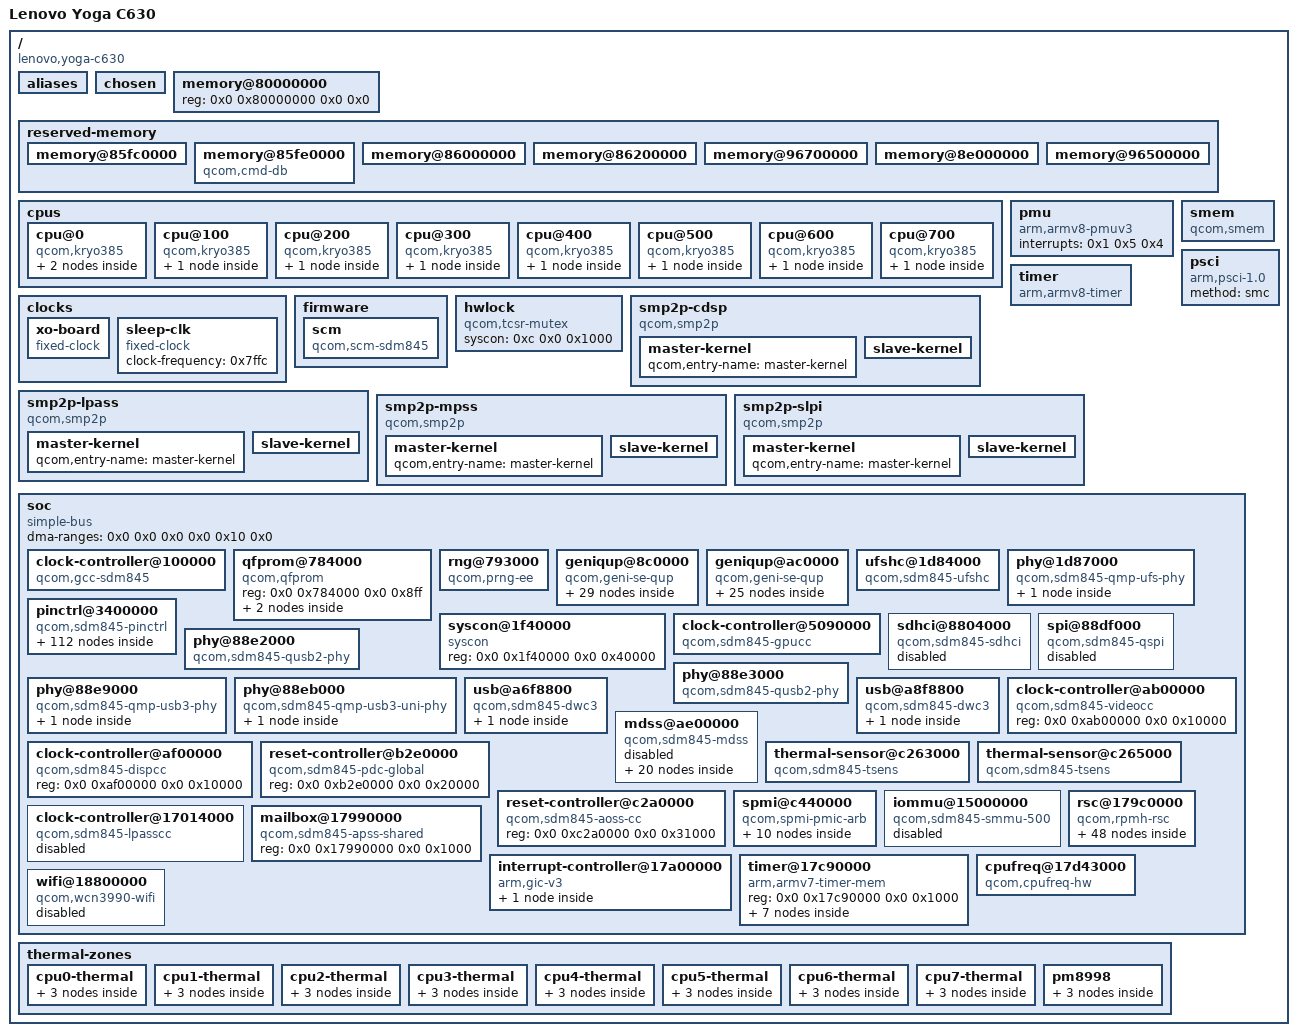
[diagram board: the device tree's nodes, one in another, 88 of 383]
/dts-v1/;

/ {
	interrupt-parent = <0x1>;
	#address-cells = <0x2>;
	#size-cells = <0x2>;
	model = "Lenovo Yoga C630";
	compatible = "lenovo,yoga-c630", "qcom,sdm845";

	aliases {
		i2c0 = "/soc/geniqup@8c0000/i2c@880000";
		i2c1 = "/soc/geniqup@8c0000/i2c@884000";
		i2c2 = "/soc/geniqup@8c0000/i2c@888000";
		i2c3 = "/soc/geniqup@8c0000/i2c@88c000";
		i2c4 = "/soc/geniqup@8c0000/i2c@890000";
		i2c5 = "/soc/geniqup@8c0000/i2c@894000";
		i2c6 = "/soc/geniqup@8c0000/i2c@898000";
		i2c7 = "/soc/geniqup@8c0000/i2c@89c000";
		i2c8 = "/soc/geniqup@ac0000/i2c@a80000";
		i2c9 = "/soc/geniqup@ac0000/i2c@a84000";
		i2c10 = "/soc/geniqup@ac0000/i2c@a88000";
		i2c11 = "/soc/geniqup@ac0000/i2c@a8c000";
		i2c12 = "/soc/geniqup@ac0000/i2c@a90000";
		i2c13 = "/soc/geniqup@ac0000/i2c@a94000";
		i2c14 = "/soc/geniqup@ac0000/i2c@a98000";
		i2c15 = "/soc/geniqup@ac0000/i2c@a9c000";
		spi0 = "/soc/geniqup@8c0000/spi@880000";
		spi1 = "/soc/geniqup@8c0000/spi@884000";
		spi2 = "/soc/geniqup@8c0000/spi@888000";
		spi3 = "/soc/geniqup@8c0000/spi@88c000";
		spi4 = "/soc/geniqup@8c0000/spi@890000";
		spi5 = "/soc/geniqup@8c0000/spi@894000";
		spi6 = "/soc/geniqup@8c0000/spi@898000";
		spi7 = "/soc/geniqup@8c0000/spi@89c000";
		spi8 = "/soc/geniqup@ac0000/spi@a80000";
		spi9 = "/soc/geniqup@ac0000/spi@a84000";
		spi10 = "/soc/geniqup@ac0000/spi@a88000";
		spi11 = "/soc/geniqup@ac0000/spi@a8c000";
		spi12 = "/soc/geniqup@ac0000/spi@a90000";
		spi13 = "/soc/geniqup@ac0000/spi@a94000";
		spi14 = "/soc/geniqup@ac0000/spi@a98000";
		spi15 = "/soc/geniqup@ac0000/spi@a9c000";
		hsuart0 = "/soc/geniqup@8c0000/serial@898000";
	};

	chosen {
	};

	memory@80000000 {
		device_type = "memory";
		reg = <0x0 0x80000000 0x0 0x0>;
	};

	reserved-memory {
		#address-cells = <0x2>;
		#size-cells = <0x2>;
		ranges;

		memory@85fc0000 {
			reg = <0x0 0x85fc0000 0x0 0x20000>;
			no-map;
		};

		memory@85fe0000 {
			compatible = "qcom,cmd-db";
			reg = <0x0 0x85fe0000 0x0 0x20000>;
			no-map;
		};

		memory@86000000 {
			reg = <0x0 0x86000000 0x0 0x200000>;
			no-map;
			phandle = <0xd>;
		};

		memory@86200000 {
			reg = <0x0 0x86200000 0x0 0x2d00000>;
			no-map;
		};

		memory@96700000 {
			reg = <0x0 0x96700000 0x0 0x100000>;
			no-map;
			phandle = <0x62>;
		};

		memory@8e000000 {
			reg = <0x0 0x8e000000 0x0 0x7800000>;
			no-map;
		};

		memory@96500000 {
			reg = <0x0 0x96500000 0x0 0x200000>;
			no-map;
		};
	};

	cpus {
		#address-cells = <0x2>;
		#size-cells = <0x0>;

		cpu@0 {
			device_type = "cpu";
			compatible = "qcom,kryo385";
			reg = <0x0 0x0>;
			enable-method = "psci";
			qcom,freq-domain = <0x2 0x0>;
			next-level-cache = <0x3>;

			l2-cache {
				compatible = "cache";
				next-level-cache = <0x4>;
				phandle = <0x3>;

				l3-cache {
					compatible = "cache";
					phandle = <0x4>;
				};
			};
		};

		cpu@100 {
			device_type = "cpu";
			compatible = "qcom,kryo385";
			reg = <0x0 0x100>;
			enable-method = "psci";
			qcom,freq-domain = <0x2 0x0>;
			next-level-cache = <0x5>;

			l2-cache {
				compatible = "cache";
				next-level-cache = <0x4>;
				phandle = <0x5>;
			};
		};

		cpu@200 {
			device_type = "cpu";
			compatible = "qcom,kryo385";
			reg = <0x0 0x200>;
			enable-method = "psci";
			qcom,freq-domain = <0x2 0x0>;
			next-level-cache = <0x6>;

			l2-cache {
				compatible = "cache";
				next-level-cache = <0x4>;
				phandle = <0x6>;
			};
		};

		cpu@300 {
			device_type = "cpu";
			compatible = "qcom,kryo385";
			reg = <0x0 0x300>;
			enable-method = "psci";
			qcom,freq-domain = <0x2 0x0>;
			next-level-cache = <0x7>;

			l2-cache {
				compatible = "cache";
				next-level-cache = <0x4>;
				phandle = <0x7>;
			};
		};

		cpu@400 {
			device_type = "cpu";
			compatible = "qcom,kryo385";
			reg = <0x0 0x400>;
			enable-method = "psci";
			qcom,freq-domain = <0x2 0x1>;
			next-level-cache = <0x8>;

			l2-cache {
				compatible = "cache";
				next-level-cache = <0x4>;
				phandle = <0x8>;
			};
		};

		cpu@500 {
			device_type = "cpu";
			compatible = "qcom,kryo385";
			reg = <0x0 0x500>;
			enable-method = "psci";
			qcom,freq-domain = <0x2 0x1>;
			next-level-cache = <0x9>;

			l2-cache {
				compatible = "cache";
				next-level-cache = <0x4>;
				phandle = <0x9>;
			};
		};

		cpu@600 {
			device_type = "cpu";
			compatible = "qcom,kryo385";
			reg = <0x0 0x600>;
			enable-method = "psci";
			qcom,freq-domain = <0x2 0x1>;
			next-level-cache = <0xa>;

			l2-cache {
				compatible = "cache";
				next-level-cache = <0x4>;
				phandle = <0xa>;
			};
		};

		cpu@700 {
			device_type = "cpu";
			compatible = "qcom,kryo385";
			reg = <0x0 0x700>;
			enable-method = "psci";
			qcom,freq-domain = <0x2 0x1>;
			next-level-cache = <0xb>;

			l2-cache {
				compatible = "cache";
				next-level-cache = <0x4>;
				phandle = <0xb>;
			};
		};
	};

	pmu {
		compatible = "arm,armv8-pmuv3";
		interrupts = <0x1 0x5 0x4>;
	};

	timer {
		compatible = "arm,armv8-timer";
		interrupts = <0x1 0x1 0x8 0x1 0x2 0x8 0x1 0x3 0x8 0x1 0x0 0x8>;
	};

	clocks {

		xo-board {
			compatible = "fixed-clock";
			#clock-cells = <0x0>;
			clock-frequency = <0x249f000>;
			clock-output-names = "xo_board";
		};

		sleep-clk {
			compatible = "fixed-clock";
			#clock-cells = <0x0>;
			clock-frequency = <0x7ffc>;
		};
	};

	firmware {

		scm {
			compatible = "qcom,scm-sdm845", "qcom,scm";
		};
	};

	hwlock {
		compatible = "qcom,tcsr-mutex";
		syscon = <0xc 0x0 0x1000>;
		#hwlock-cells = <0x1>;
		phandle = <0xe>;
	};

	smem {
		compatible = "qcom,smem";
		memory-region = <0xd>;
		hwlocks = <0xe 0x3>;
	};

	smp2p-cdsp {
		compatible = "qcom,smp2p";
		qcom,smem = <0x5e 0x1b0>;
		interrupts = <0x0 0x240 0x1>;
		mboxes = <0xf 0x6>;
		qcom,local-pid = <0x0>;
		qcom,remote-pid = <0x5>;

		master-kernel {
			qcom,entry-name = "master-kernel";
			#qcom,smem-state-cells = <0x1>;
		};

		slave-kernel {
			qcom,entry-name = "slave-kernel";
			interrupt-controller;
			#interrupt-cells = <0x2>;
		};
	};

	smp2p-lpass {
		compatible = "qcom,smp2p";
		qcom,smem = <0x1bb 0x1ad>;
		interrupts = <0x0 0x9e 0x1>;
		mboxes = <0xf 0xa>;
		qcom,local-pid = <0x0>;
		qcom,remote-pid = <0x2>;

		master-kernel {
			qcom,entry-name = "master-kernel";
			#qcom,smem-state-cells = <0x1>;
		};

		slave-kernel {
			qcom,entry-name = "slave-kernel";
			interrupt-controller;
			#interrupt-cells = <0x2>;
		};
	};

	smp2p-mpss {
		compatible = "qcom,smp2p";
		qcom,smem = <0x1b3 0x1ac>;
		interrupts = <0x0 0x1c3 0x1>;
		mboxes = <0xf 0xe>;
		qcom,local-pid = <0x0>;
		qcom,remote-pid = <0x1>;

		master-kernel {
			qcom,entry-name = "master-kernel";
			#qcom,smem-state-cells = <0x1>;
		};

		slave-kernel {
			qcom,entry-name = "slave-kernel";
			interrupt-controller;
			#interrupt-cells = <0x2>;
		};
	};

	smp2p-slpi {
		compatible = "qcom,smp2p";
		qcom,smem = <0x1e1 0x1ae>;
		interrupts = <0x0 0xac 0x1>;
		mboxes = <0xf 0x1a>;
		qcom,local-pid = <0x0>;
		qcom,remote-pid = <0x3>;

		master-kernel {
			qcom,entry-name = "master-kernel";
			#qcom,smem-state-cells = <0x1>;
		};

		slave-kernel {
			qcom,entry-name = "slave-kernel";
			interrupt-controller;
			#interrupt-cells = <0x2>;
		};
	};

	psci {
		compatible = "arm,psci-1.0";
		method = "smc";
	};

	soc {
		#address-cells = <0x2>;
		#size-cells = <0x2>;
		ranges = <0x0 0x0 0x0 0x0 0x10 0x0>;
		dma-ranges = <0x0 0x0 0x0 0x0 0x10 0x0>;
		compatible = "simple-bus";

		clock-controller@100000 {
			compatible = "qcom,gcc-sdm845";
			reg = <0x0 0x100000 0x0 0x1f0000>;
			#clock-cells = <0x1>;
			#reset-cells = <0x1>;
			#power-domain-cells = <0x1>;
			protected-clocks = <0xbc 0xbb 0xbd>;
			phandle = <0x10>;
		};

		qfprom@784000 {
			compatible = "qcom,qfprom";
			reg = <0x0 0x784000 0x0 0x8ff>;
			#address-cells = <0x1>;
			#size-cells = <0x1>;

			hstx-trim-primary@1eb {
				reg = <0x1eb 0x1>;
				bits = <0x1 0x4>;
				phandle = <0x4f>;
			};

			hstx-trim-secondary@1eb {
				reg = <0x1eb 0x2>;
				bits = <0x6 0x4>;
				phandle = <0x52>;
			};
		};

		rng@793000 {
			compatible = "qcom,prng-ee";
			reg = <0x0 0x793000 0x0 0x1000>;
			clocks = <0x10 0x40>;
			clock-names = "core";
		};

		geniqup@8c0000 {
			compatible = "qcom,geni-se-qup";
			reg = <0x0 0x8c0000 0x0 0x6000>;
			clock-names = "m-ahb", "s-ahb";
			clocks = <0x10 0x64 0x10 0x65>;
			#address-cells = <0x2>;
			#size-cells = <0x2>;
			ranges;
			status = "okay";

			i2c@880000 {
				compatible = "qcom,geni-i2c";
				reg = <0x0 0x880000 0x0 0x4000>;
				clock-names = "se";
				clocks = <0x10 0x44>;
				pinctrl-names = "default";
				pinctrl-0 = <0x11>;
				interrupts = <0x0 0x259 0x4>;
				#address-cells = <0x1>;
				#size-cells = <0x0>;
				status = "disabled";
			};

			spi@880000 {
				compatible = "qcom,geni-spi";
				reg = <0x0 0x880000 0x0 0x4000>;
				clock-names = "se";
				clocks = <0x10 0x44>;
				pinctrl-names = "default";
				pinctrl-0 = <0x12>;
				interrupts = <0x0 0x259 0x4>;
				#address-cells = <0x1>;
				#size-cells = <0x0>;
				status = "disabled";
			};

			serial@880000 {
				compatible = "qcom,geni-uart";
				reg = <0x0 0x880000 0x0 0x4000>;
				clock-names = "se";
				clocks = <0x10 0x44>;
				pinctrl-names = "default";
				pinctrl-0 = <0x13>;
				interrupts = <0x0 0x259 0x4>;
				status = "disabled";
			};

			i2c@884000 {
				compatible = "qcom,geni-i2c";
				reg = <0x0 0x884000 0x0 0x4000>;
				clock-names = "se";
				clocks = <0x10 0x46>;
				pinctrl-names = "default";
				pinctrl-0 = <0x14>;
				interrupts = <0x0 0x25a 0x4>;
				#address-cells = <0x1>;
				#size-cells = <0x0>;
				status = "okay";
				clock-frequency = <0x61a80>;

				hid@2c {
					compatible = "hid-over-i2c";
					reg = <0x2c>;
					hid-descr-addr = <0x20>;
					interrupts-extended = <0x15 0x25 0x1>;
					pinctrl-names = "default";
					pinctrl-0 = <0x16>;
				};

				battery@70 {
					compatible = "some,battery";
					reg = <0x70>;
				};
			};

			spi@884000 {
				compatible = "qcom,geni-spi";
				reg = <0x0 0x884000 0x0 0x4000>;
				clock-names = "se";
				clocks = <0x10 0x46>;
				pinctrl-names = "default";
				pinctrl-0 = <0x17>;
				interrupts = <0x0 0x25a 0x4>;
				#address-cells = <0x1>;
				#size-cells = <0x0>;
				status = "disabled";
			};

			serial@884000 {
				compatible = "qcom,geni-uart";
				reg = <0x0 0x884000 0x0 0x4000>;
				clock-names = "se";
				clocks = <0x10 0x46>;
				pinctrl-names = "default";
				pinctrl-0 = <0x18>;
				interrupts = <0x0 0x25a 0x4>;
				status = "disabled";
			};

			i2c@888000 {
				compatible = "qcom,geni-i2c";
				reg = <0x0 0x888000 0x0 0x4000>;
				clock-names = "se";
				clocks = <0x10 0x48>;
				pinctrl-names = "default";
				pinctrl-0 = <0x19>;
				interrupts = <0x0 0x25b 0x4>;
				#address-cells = <0x1>;
				#size-cells = <0x0>;
				status = "disabled";
			};

			spi@888000 {
				compatible = "qcom,geni-spi";
				reg = <0x0 0x888000 0x0 0x4000>;
				clock-names = "se";
				clocks = <0x10 0x48>;
				pinctrl-names = "default";
				pinctrl-0 = <0x1a>;
				interrupts = <0x0 0x25b 0x4>;
				#address-cells = <0x1>;
				#size-cells = <0x0>;
				status = "disabled";
			};

			serial@888000 {
				compatible = "qcom,geni-uart";
				reg = <0x0 0x888000 0x0 0x4000>;
				clock-names = "se";
				clocks = <0x10 0x48>;
				pinctrl-names = "default";
				pinctrl-0 = <0x1b>;
				interrupts = <0x0 0x25b 0x4>;
				status = "disabled";
			};

			i2c@88c000 {
				compatible = "qcom,geni-i2c";
				reg = <0x0 0x88c000 0x0 0x4000>;
				clock-names = "se";
				clocks = <0x10 0x4a>;
				pinctrl-names = "default";
				pinctrl-0 = <0x1c>;
				interrupts = <0x0 0x25c 0x4>;
				#address-cells = <0x1>;
				#size-cells = <0x0>;
				status = "okay";
				clock-frequency = <0x61a80>;

				hid@15 {
					compatible = "hid-over-i2c";
					reg = <0x15>;
					hid-descr-addr = <0x1>;
					interrupts-extended = <0x15 0x25 0x1>;
				};
			};

			spi@88c000 {
				compatible = "qcom,geni-spi";
				reg = <0x0 0x88c000 0x0 0x4000>;
				clock-names = "se";
				clocks = <0x10 0x4a>;
				pinctrl-names = "default";
				pinctrl-0 = <0x1d>;
				interrupts = <0x0 0x25c 0x4>;
				#address-cells = <0x1>;
				#size-cells = <0x0>;
				status = "disabled";
			};

			serial@88c000 {
				compatible = "qcom,geni-uart";
				reg = <0x0 0x88c000 0x0 0x4000>;
				clock-names = "se";
				clocks = <0x10 0x4a>;
				pinctrl-names = "default";
				pinctrl-0 = <0x1e>;
				interrupts = <0x0 0x25c 0x4>;
				status = "disabled";
			};

			i2c@890000 {
				compatible = "qcom,geni-i2c";
				reg = <0x0 0x890000 0x0 0x4000>;
				clock-names = "se";
				clocks = <0x10 0x4c>;
				pinctrl-names = "default";
				pinctrl-0 = <0x1f>;
				interrupts = <0x0 0x25d 0x4>;
				#address-cells = <0x1>;
				#size-cells = <0x0>;
				status = "disabled";
			};

			spi@890000 {
				compatible = "qcom,geni-spi";
				reg = <0x0 0x890000 0x0 0x4000>;
				clock-names = "se";
				clocks = <0x10 0x4c>;
				pinctrl-names = "default";
				pinctrl-0 = <0x20>;
				interrupts = <0x0 0x25d 0x4>;
				#address-cells = <0x1>;
				#size-cells = <0x0>;
				status = "disabled";
			};

			serial@890000 {
				compatible = "qcom,geni-uart";
				reg = <0x0 0x890000 0x0 0x4000>;
				clock-names = "se";
				clocks = <0x10 0x4c>;
				pinctrl-names = "default";
				pinctrl-0 = <0x21>;
				interrupts = <0x0 0x25d 0x4>;
				status = "disabled";
			};

			i2c@894000 {
				compatible = "qcom,geni-i2c";
				reg = <0x0 0x894000 0x0 0x4000>;
				clock-names = "se";
				clocks = <0x10 0x4e>;
				pinctrl-names = "default";
				pinctrl-0 = <0x22>;
				interrupts = <0x0 0x25e 0x4>;
				#address-cells = <0x1>;
				#size-cells = <0x0>;
				status = "okay";
				clock-frequency = <0x61a80>;

				hid@10 {
					compatible = "hid-over-i2c";
					reg = <0x10>;
					hid-descr-addr = <0x1>;
					interrupts-extended = <0x15 0x7d 0x2>;
					pinctrl-names = "default";
					pinctrl-0 = <0x23>;
				};
			};

			spi@894000 {
				compatible = "qcom,geni-spi";
				reg = <0x0 0x894000 0x0 0x4000>;
				clock-names = "se";
				clocks = <0x10 0x4e>;
				pinctrl-names = "default";
				pinctrl-0 = <0x24>;
				interrupts = <0x0 0x25e 0x4>;
				#address-cells = <0x1>;
				#size-cells = <0x0>;
				status = "disabled";
			};

			serial@894000 {
				compatible = "qcom,geni-uart";
				reg = <0x0 0x894000 0x0 0x4000>;
				clock-names = "se";
				clocks = <0x10 0x4e>;
				pinctrl-names = "default";
				pinctrl-0 = <0x25>;
				interrupts = <0x0 0x25e 0x4>;
				status = "disabled";
			};

			i2c@898000 {
				compatible = "qcom,geni-i2c";
				reg = <0x0 0x898000 0x0 0x4000>;
				clock-names = "se";
				clocks = <0x10 0x50>;
				pinctrl-names = "default";
				pinctrl-0 = <0x26>;
				interrupts = <0x0 0x25f 0x4>;
				#address-cells = <0x1>;
				#size-cells = <0x0>;
				status = "disabled";
			};

			spi@898000 {
				compatible = "qcom,geni-spi";
				reg = <0x0 0x898000 0x0 0x4000>;
				clock-names = "se";
				clocks = <0x10 0x50>;
				pinctrl-names = "default";
				pinctrl-0 = <0x27>;
				interrupts = <0x0 0x25f 0x4>;
				#address-cells = <0x1>;
				#size-cells = <0x0>;
				status = "disabled";
			};

			serial@898000 {
				compatible = "qcom,geni-uart";
				reg = <0x0 0x898000 0x0 0x4000>;
				clock-names = "se";
				clocks = <0x10 0x50>;
				pinctrl-names = "default";
				pinctrl-0 = <0x28>;
				interrupts = <0x0 0x25f 0x4>;
				status = "okay";

				bluetooth {
					compatible = "qcom,wcn3990-bt";
					vddio-supply = <0x29>;
					vddxo-supply = <0x2a>;
					vddrf-supply = <0x2b>;
					vddch0-supply = <0x2c>;
					max-speed = <0x30d400>;
				};
			};

			i2c@89c000 {
				compatible = "qcom,geni-i2c";
				reg = <0x0 0x89c000 0x0 0x4000>;
				clock-names = "se";
				clocks = <0x10 0x52>;
				pinctrl-names = "default";
				pinctrl-0 = <0x2d>;
				interrupts = <0x0 0x260 0x4>;
				#address-cells = <0x1>;
				#size-cells = <0x0>;
				status = "disabled";
			};

			spi@89c000 {
				compatible = "qcom,geni-spi";
				reg = <0x0 0x89c000 0x0 0x4000>;
				clock-names = "se";
				clocks = <0x10 0x52>;
				pinctrl-names = "default";
				pinctrl-0 = <0x2e>;
				interrupts = <0x0 0x260 0x4>;
				#address-cells = <0x1>;
				#size-cells = <0x0>;
				status = "disabled";
			};

			serial@89c000 {
				compatible = "qcom,geni-uart";
				reg = <0x0 0x89c000 0x0 0x4000>;
				clock-names = "se";
				clocks = <0x10 0x52>;
				pinctrl-names = "default";
				pinctrl-0 = <0x2f>;
				interrupts = <0x0 0x260 0x4>;
				status = "disabled";
			};
		};

		geniqup@ac0000 {
			compatible = "qcom,geni-se-qup";
			reg = <0x0 0xac0000 0x0 0x6000>;
			clock-names = "m-ahb", "s-ahb";
			clocks = <0x10 0x66 0x10 0x67>;
			#address-cells = <0x2>;
			#size-cells = <0x2>;
			ranges;
			status = "okay";

			i2c@a80000 {
				compatible = "qcom,geni-i2c";
				reg = <0x0 0xa80000 0x0 0x4000>;
				clock-names = "se";
				clocks = <0x10 0x54>;
				pinctrl-names = "default";
				pinctrl-0 = <0x30>;
				interrupts = <0x0 0x161 0x4>;
				#address-cells = <0x1>;
				#size-cells = <0x0>;
				status = "disabled";
			};

			spi@a80000 {
				compatible = "qcom,geni-spi";
				reg = <0x0 0xa80000 0x0 0x4000>;
				clock-names = "se";
				clocks = <0x10 0x54>;
				pinctrl-names = "default";
				pinctrl-0 = <0x31>;
				interrupts = <0x0 0x161 0x4>;
				#address-cells = <0x1>;
				#size-cells = <0x0>;
				status = "disabled";
			};

			serial@a80000 {
				compatible = "qcom,geni-uart";
				reg = <0x0 0xa80000 0x0 0x4000>;
				clock-names = "se";
				clocks = <0x10 0x54>;
				pinctrl-names = "default";
				pinctrl-0 = <0x32>;
				interrupts = <0x0 0x161 0x4>;
				status = "disabled";
			};

			i2c@a84000 {
				compatible = "qcom,geni-i2c";
				reg = <0x0 0xa84000 0x0 0x4000>;
				clock-names = "se";
				clocks = <0x10 0x56>;
				pinctrl-names = "default";
				pinctrl-0 = <0x33>;
				interrupts = <0x0 0x162 0x4>;
				#address-cells = <0x1>;
				#size-cells = <0x0>;
				status = "disabled";
			};

			spi@a84000 {
				compatible = "qcom,geni-spi";
				reg = <0x0 0xa84000 0x0 0x4000>;
				clock-names = "se";
				clocks = <0x10 0x56>;
				pinctrl-names = "default";
				pinctrl-0 = <0x34>;
				interrupts = <0x0 0x162 0x4>;
				#address-cells = <0x1>;
				#size-cells = <0x0>;
				status = "disabled";
			};

			serial@a84000 {
				compatible = "qcom,geni-debug-uart";
				reg = <0x0 0xa84000 0x0 0x4000>;
				clock-names = "se";
				clocks = <0x10 0x56>;
				pinctrl-names = "default";
				pinctrl-0 = <0x35>;
				interrupts = <0x0 0x162 0x4>;
				status = "disabled";
			};

			i2c@a88000 {
				compatible = "qcom,geni-i2c";
				reg = <0x0 0xa88000 0x0 0x4000>;
				clock-names = "se";
				clocks = <0x10 0x58>;
				pinctrl-names = "default";
				pinctrl-0 = <0x36>;
				interrupts = <0x0 0x163 0x4>;
				#address-cells = <0x1>;
				#size-cells = <0x0>;
				status = "disabled";
			};

			spi@a88000 {
				compatible = "qcom,geni-spi";
				reg = <0x0 0xa88000 0x0 0x4000>;
				clock-names = "se";
				clocks = <0x10 0x58>;
				pinctrl-names = "default";
				pinctrl-0 = <0x37>;
				interrupts = <0x0 0x163 0x4>;
				#address-cells = <0x1>;
				#size-cells = <0x0>;
				status = "disabled";
			};

			serial@a88000 {
				compatible = "qcom,geni-uart";
				reg = <0x0 0xa88000 0x0 0x4000>;
				clock-names = "se";
				clocks = <0x10 0x58>;
				pinctrl-names = "default";
				pinctrl-0 = <0x38>;
				interrupts = <0x0 0x163 0x4>;
				status = "disabled";
			};

			i2c@a8c000 {
				compatible = "qcom,geni-i2c";
				reg = <0x0 0xa8c000 0x0 0x4000>;
				clock-names = "se";
				clocks = <0x10 0x5a>;
				pinctrl-names = "default";
				pinctrl-0 = <0x39>;
				interrupts = <0x0 0x164 0x4>;
				#address-cells = <0x1>;
				#size-cells = <0x0>;
				status = "okay";
				clock-frequency = <0x61a80>;

				hid@5c {
					compatible = "hid-over-i2c";
					reg = <0x5c>;
					hid-descr-addr = <0x1>;
					interrupts-extended = <0x15 0x5c 0x8>;
					pinctrl-names = "default";
					pinctrl-0 = <0x3a>;
				};
			};

			spi@a8c000 {
				compatible = "qcom,geni-spi";
				reg = <0x0 0xa8c000 0x0 0x4000>;
				clock-names = "se";
				clocks = <0x10 0x5a>;
				pinctrl-names = "default";
				pinctrl-0 = <0x3b>;
				interrupts = <0x0 0x164 0x4>;
				#address-cells = <0x1>;
				#size-cells = <0x0>;
				status = "disabled";
			};

			serial@a8c000 {
				compatible = "qcom,geni-uart";
				reg = <0x0 0xa8c000 0x0 0x4000>;
				clock-names = "se";
				clocks = <0x10 0x5a>;
				pinctrl-names = "default";
				pinctrl-0 = <0x3c>;
				interrupts = <0x0 0x164 0x4>;
				status = "disabled";
			};

			i2c@a90000 {
				compatible = "qcom,geni-i2c";
				reg = <0x0 0xa90000 0x0 0x4000>;
				clock-names = "se";
				clocks = <0x10 0x5c>;
				pinctrl-names = "default";
				pinctrl-0 = <0x3d>;
				interrupts = <0x0 0x165 0x4>;
				#address-cells = <0x1>;
				#size-cells = <0x0>;
				status = "disabled";
			};

			spi@a90000 {
				compatible = "qcom,geni-spi";
				reg = <0x0 0xa90000 0x0 0x4000>;
				clock-names = "se";
				clocks = <0x10 0x5c>;
				pinctrl-names = "default";
				pinctrl-0 = <0x3e>;
				interrupts = <0x0 0x165 0x4>;
				#address-cells = <0x1>;
				#size-cells = <0x0>;
				status = "disabled";
			};

			serial@a90000 {
				compatible = "qcom,geni-uart";
				reg = <0x0 0xa90000 0x0 0x4000>;
				clock-names = "se";
				clocks = <0x10 0x5c>;
				pinctrl-names = "default";
				pinctrl-0 = <0x3f>;
				interrupts = <0x0 0x165 0x4>;
				status = "disabled";
			};

			i2c@a94000 {
				compatible = "qcom,geni-i2c";
				reg = <0x0 0xa94000 0x0 0x4000>;
				clock-names = "se";
				clocks = <0x10 0x5e>;
				pinctrl-names = "default";
				pinctrl-0 = <0x40>;
				interrupts = <0x0 0x166 0x4>;
				#address-cells = <0x1>;
				#size-cells = <0x0>;
				status = "disabled";
			};

			spi@a94000 {
				compatible = "qcom,geni-spi";
				reg = <0x0 0xa94000 0x0 0x4000>;
				clock-names = "se";
				clocks = <0x10 0x5e>;
				pinctrl-names = "default";
				pinctrl-0 = <0x41>;
				interrupts = <0x0 0x166 0x4>;
				#address-cells = <0x1>;
				#size-cells = <0x0>;
				status = "disabled";
			};

			serial@a94000 {
				compatible = "qcom,geni-uart";
				reg = <0x0 0xa94000 0x0 0x4000>;
				clock-names = "se";
				clocks = <0x10 0x5e>;
				pinctrl-names = "default";
				pinctrl-0 = <0x42>;
				interrupts = <0x0 0x166 0x4>;
				status = "disabled";
			};

			i2c@a98000 {
				compatible = "qcom,geni-i2c";
				reg = <0x0 0xa98000 0x0 0x4000>;
				clock-names = "se";
				clocks = <0x10 0x60>;
				pinctrl-names = "default";
				pinctrl-0 = <0x43>;
				interrupts = <0x0 0x167 0x4>;
				#address-cells = <0x1>;
				#size-cells = <0x0>;
				status = "disabled";
			};

			spi@a98000 {
				compatible = "qcom,geni-spi";
				reg = <0x0 0xa98000 0x0 0x4000>;
				clock-names = "se";
				clocks = <0x10 0x60>;
				pinctrl-names = "default";
				pinctrl-0 = <0x44>;
				interrupts = <0x0 0x167 0x4>;
				#address-cells = <0x1>;
				#size-cells = <0x0>;
				status = "disabled";
			};

			serial@a98000 {
				compatible = "qcom,geni-uart";
				reg = <0x0 0xa98000 0x0 0x4000>;
				clock-names = "se";
				clocks = <0x10 0x60>;
				pinctrl-names = "default";
				pinctrl-0 = <0x45>;
				interrupts = <0x0 0x167 0x4>;
				status = "disabled";
			};

			i2c@a9c000 {
				compatible = "qcom,geni-i2c";
				reg = <0x0 0xa9c000 0x0 0x4000>;
				clock-names = "se";
				clocks = <0x10 0x62>;
				pinctrl-names = "default";
				pinctrl-0 = <0x46>;
				interrupts = <0x0 0x168 0x4>;
				#address-cells = <0x1>;
				#size-cells = <0x0>;
				status = "disabled";
			};

			spi@a9c000 {
				compatible = "qcom,geni-spi";
				reg = <0x0 0xa9c000 0x0 0x4000>;
				clock-names = "se";
				clocks = <0x10 0x62>;
				pinctrl-names = "default";
				pinctrl-0 = <0x47>;
				interrupts = <0x0 0x168 0x4>;
				#address-cells = <0x1>;
				#size-cells = <0x0>;
				status = "disabled";
			};

			serial@a9c000 {
				compatible = "qcom,geni-uart";
				reg = <0x0 0xa9c000 0x0 0x4000>;
				clock-names = "se";
				clocks = <0x10 0x62>;
				pinctrl-names = "default";
				pinctrl-0 = <0x48>;
				interrupts = <0x0 0x168 0x4>;
				status = "disabled";
			};
		};

		ufshc@1d84000 {
			compatible = "qcom,sdm845-ufshc", "qcom,ufshc", "jedec,ufs-2.0";
			reg = <0x0 0x1d84000 0x0 0x2500>;
			interrupts = <0x0 0x109 0x4>;
			phys = <0x49>;
			phy-names = "ufsphy";
			lanes-per-direction = <0x2>;
			power-domains = <0x10 0x3>;
			iommus = <0x4a 0x100 0xf>;
			clock-names = "core_clk", "bus_aggr_clk", "iface_clk", "core_clk_unipro", "ref_clk", "tx_lane0_sync_clk", "rx_lane0_sync_clk", "rx_lane1_sync_clk";
			clocks = <0x10 0x82 0x10 0x2 0x10 0x81 0x10 0x8b 0x4b 0x0 0x10 0x8a 0x10 0x88 0x10 0x89>;
			freq-table-hz = <0x2faf080 0xbebc200 0x0 0x0 0x0 0x0 0x23c3460 0x8f0d180 0x0 0x0 0x0 0x0 0x0 0x0 0x0 0x0>;
			status = "okay";
			vcc-supply = <0x4c>;
			vcc-max-microamp = <0x927c0>;
		};

		phy@1d87000 {
			compatible = "qcom,sdm845-qmp-ufs-phy";
			reg = <0x0 0x1d87000 0x0 0x18c>;
			#address-cells = <0x2>;
			#size-cells = <0x2>;
			ranges;
			clock-names = "ref", "ref_aux";
			clocks = <0x10 0x80 0x10 0x86>;
			status = "okay";
			vdda-phy-supply = <0x4d>;
			vdda-pll-supply = <0x4e>;

			lanes@1d87400 {
				reg = <0x0 0x1d87400 0x0 0x108 0x0 0x1d87600 0x0 0x1e0 0x0 0x1d87c00 0x0 0x1dc 0x0 0x1d87800 0x0 0x108 0x0 0x1d87a00 0x0 0x1e0>;
				#phy-cells = <0x0>;
				phandle = <0x49>;
			};
		};

		syscon@1f40000 {
			compatible = "syscon";
			reg = <0x0 0x1f40000 0x0 0x40000>;
			phandle = <0xc>;
		};

		pinctrl@3400000 {
			compatible = "qcom,sdm845-pinctrl";
			reg = <0x0 0x3400000 0x0 0xc00000>;
			interrupts = <0x0 0xd0 0x4>;
			gpio-controller;
			#gpio-cells = <0x2>;
			interrupt-controller;
			#interrupt-cells = <0x2>;
			gpio-ranges = <0x15 0x0 0x0 0x96>;
			gpio-reserved-ranges = <0x0 0x4 0x51 0x4>;
			phandle = <0x15>;

			qspi-clk {

				pinmux {
					pins = "gpio95";
					function = "qspi_clk";
				};
			};

			qspi-cs0 {

				pinmux {
					pins = "gpio90";
					function = "qspi_cs";
				};
			};

			qspi-cs1 {

				pinmux {
					pins = "gpio89";
					function = "qspi_cs";
				};
			};

			qspi-data01 {

				pinmux-data {
					pins = "gpio91", "gpio92";
					function = "qspi_data";
				};
			};

			qspi-data12 {

				pinmux-data {
					pins = "gpio93", "gpio94";
					function = "qspi_data";
				};
			};

			qup-i2c0-default {
				phandle = <0x11>;

				pinmux {
					pins = "gpio0", "gpio1";
					function = "qup0";
				};
			};

			qup-i2c1-default {
				phandle = <0x14>;

				pinmux {
					pins = "gpio17", "gpio18";
					function = "qup1";
				};
			};

			qup-i2c2-default {
				phandle = <0x19>;

				pinmux {
					pins = "gpio27", "gpio28";
					function = "qup2";
				};
			};

			qup-i2c3-default {
				phandle = <0x1c>;

				pinmux {
					pins = "gpio41", "gpio42";
					function = "qup3";
				};
			};

			qup-i2c4-default {
				phandle = <0x1f>;

				pinmux {
					pins = "gpio89", "gpio90";
					function = "qup4";
				};
			};

			qup-i2c5-default {
				phandle = <0x22>;

				pinmux {
					pins = "gpio85", "gpio86";
					function = "qup5";
				};
			};

			qup-i2c6-default {
				phandle = <0x26>;

				pinmux {
					pins = "gpio45", "gpio46";
					function = "qup6";
				};
			};

			qup-i2c7-default {
				phandle = <0x2d>;

				pinmux {
					pins = "gpio93", "gpio94";
					function = "qup7";
				};
			};

			qup-i2c8-default {
				phandle = <0x30>;

				pinmux {
					pins = "gpio65", "gpio66";
					function = "qup8";
				};
			};

			qup-i2c9-default {
				phandle = <0x33>;

				pinmux {
					pins = "gpio6", "gpio7";
					function = "qup9";
				};
			};

			qup-i2c10-default {
				phandle = <0x36>;

				pinmux {
					pins = "gpio55", "gpio56";
					function = "qup10";
				};
			};

			qup-i2c11-default {
				phandle = <0x39>;

				pinmux {
					pins = "gpio31", "gpio32";
					function = "qup11";
				};
			};

			qup-i2c12-default {
				drive-strength = <0x2>;
				bias-disable;
				phandle = <0x3d>;

				pinmux {
					pins = "gpio49", "gpio50";
					function = "qup12";
				};
			};

			qup-i2c13-default {
				phandle = <0x40>;

				pinmux {
					pins = "gpio105", "gpio106";
					function = "qup13";
				};
			};

			qup-i2c14-default {
				phandle = <0x43>;

				pinmux {
					pins = "gpio33", "gpio34";
					function = "qup14";
				};
			};

			qup-i2c15-default {
				phandle = <0x46>;

				pinmux {
					pins = "gpio81", "gpio82";
					function = "qup15";
				};
			};

			qup-spi0-default {
				phandle = <0x12>;

				pinmux {
					pins = "gpio0", "gpio1", "gpio2", "gpio3";
					function = "qup0";
				};
			};

			qup-spi1-default {
				phandle = <0x17>;

				pinmux {
					pins = "gpio17", "gpio18", "gpio19", "gpio20";
					function = "qup1";
				};
			};

			qup-spi2-default {
				phandle = <0x1a>;

				pinmux {
					pins = "gpio27", "gpio28", "gpio29", "gpio30";
					function = "qup2";
				};
			};

			qup-spi3-default {
				phandle = <0x1d>;

				pinmux {
					pins = "gpio41", "gpio42", "gpio43", "gpio44";
					function = "qup3";
				};
			};

			qup-spi4-default {
				phandle = <0x20>;

				pinmux {
					pins = "gpio89", "gpio90", "gpio91", "gpio92";
					function = "qup4";
				};
			};

			qup-spi5-default {
				phandle = <0x24>;

				pinmux {
					pins = "gpio85", "gpio86", "gpio87", "gpio88";
					function = "qup5";
				};
			};

			qup-spi6-default {
				phandle = <0x27>;

				pinmux {
					pins = "gpio45", "gpio46", "gpio47", "gpio48";
					function = "qup6";
				};
			};

			qup-spi7-default {
				phandle = <0x2e>;

				pinmux {
					pins = "gpio93", "gpio94", "gpio95", "gpio96";
					function = "qup7";
				};
			};

			qup-spi8-default {
				phandle = <0x31>;

				pinmux {
					pins = "gpio65", "gpio66", "gpio67", "gpio68";
					function = "qup8";
				};
			};

			qup-spi9-default {
				phandle = <0x34>;

				pinmux {
					pins = "gpio6", "gpio7", "gpio4", "gpio5";
					function = "qup9";
				};
			};

			qup-spi10-default {
				phandle = <0x37>;

				pinmux {
					pins = "gpio55", "gpio56", "gpio53", "gpio54";
					function = "qup10";
				};
			};

			qup-spi11-default {
				phandle = <0x3b>;

				pinmux {
					pins = "gpio31", "gpio32", "gpio33", "gpio34";
					function = "qup11";
				};
			};

			qup-spi12-default {
				phandle = <0x3e>;

				pinmux {
					pins = "gpio49", "gpio50", "gpio51", "gpio52";
					function = "qup12";
				};
			};

			qup-spi13-default {
				phandle = <0x41>;

				pinmux {
					pins = "gpio105", "gpio106", "gpio107", "gpio108";
					function = "qup13";
				};
			};

			qup-spi14-default {
				phandle = <0x44>;

				pinmux {
					pins = "gpio33", "gpio34", "gpio31", "gpio32";
					function = "qup14";
				};
			};

			qup-spi15-default {
				phandle = <0x47>;

				pinmux {
					pins = "gpio81", "gpio82", "gpio83", "gpio84";
					function = "qup15";
				};
			};

			qup-uart0-default {
				phandle = <0x13>;

				pinmux {
					pins = "gpio2", "gpio3";
					function = "qup0";
				};
			};

			qup-uart1-default {
				phandle = <0x18>;

				pinmux {
					pins = "gpio19", "gpio20";
					function = "qup1";
				};
			};

			qup-uart2-default {
				phandle = <0x1b>;

				pinmux {
					pins = "gpio29", "gpio30";
					function = "qup2";
				};
			};

			qup-uart3-default {
				phandle = <0x1e>;

				pinmux {
					pins = "gpio43", "gpio44";
					function = "qup3";
				};
			};

			qup-uart4-default {
				phandle = <0x21>;

				pinmux {
					pins = "gpio91", "gpio92";
					function = "qup4";
				};
			};

			qup-uart5-default {
				phandle = <0x25>;

				pinmux {
					pins = "gpio87", "gpio88";
					function = "qup5";
				};
			};

			qup-uart6-default {
				phandle = <0x28>;

				pinmux {
					pins = "gpio45", "gpio46", "gpio47", "gpio48";
					function = "qup6";
				};

				cts {
					pins = "gpio45";
					bias-pull-down;
				};

				rts-tx {
					pins = "gpio46", "gpio47";
					drive-strength = <0x2>;
					bias-disable;
				};

				rx {
					pins = "gpio48";
					bias-pull-up;
				};
			};

			qup-uart7-default {
				phandle = <0x2f>;

				pinmux {
					pins = "gpio95", "gpio96";
					function = "qup7";
				};
			};

			qup-uart8-default {
				phandle = <0x32>;

				pinmux {
					pins = "gpio67", "gpio68";
					function = "qup8";
				};
			};

			qup-uart9-default {
				phandle = <0x35>;

				pinmux {
					pins = "gpio4", "gpio5";
					function = "qup9";
				};
			};

			qup-uart10-default {
				phandle = <0x38>;

				pinmux {
					pins = "gpio53", "gpio54";
					function = "qup10";
				};
			};

			qup-uart11-default {
				phandle = <0x3c>;

				pinmux {
					pins = "gpio33", "gpio34";
					function = "qup11";
				};
			};

			qup-uart12-default {
				phandle = <0x3f>;

				pinmux {
					pins = "gpio51", "gpio52";
					function = "qup12";
				};
			};

			qup-uart13-default {
				phandle = <0x42>;

				pinmux {
					pins = "gpio107", "gpio108";
					function = "qup13";
				};
			};

			qup-uart14-default {
				phandle = <0x45>;

				pinmux {
					pins = "gpio31", "gpio32";
					function = "qup14";
				};
			};

			qup-uart15-default {
				phandle = <0x48>;

				pinmux {
					pins = "gpio83", "gpio84";
					function = "qup15";
				};
			};

			i2c2-hid-active {
				pins = <0x25>;
				function = "gpio";
				input-enable;
				bias-pull-up;
				drive-strength = <0x2>;
				phandle = <0x16>;
			};

			i2c6-hid-active {
				pins = <0x7d>;
				function = "gpio";
				input-enable;
				bias-pull-up;
				drive-strength = <0x2>;
				phandle = <0x23>;
			};

			i2c12-hid-active {
				pins = <0x5c>;
				function = "gpio";
				input-enable;
				bias-pull-up;
				drive-strength = <0x2>;
				phandle = <0x3a>;
			};
		};

		clock-controller@5090000 {
			compatible = "qcom,sdm845-gpucc";
			reg = <0x0 0x5090000 0x0 0x9000>;
			#clock-cells = <0x1>;
			#reset-cells = <0x1>;
			#power-domain-cells = <0x1>;
			clocks = <0x4b 0x0>;
			clock-names = "xo";
		};

		sdhci@8804000 {
			compatible = "qcom,sdm845-sdhci", "qcom,sdhci-msm-v5";
			reg = <0x0 0x8804000 0x0 0x1000>;
			interrupts = <0x0 0xcc 0x4 0x0 0xde 0x4>;
			interrupt-names = "hc_irq", "pwr_irq";
			clocks = <0x10 0x68 0x10 0x69>;
			clock-names = "iface", "core";
			status = "disabled";
		};

		spi@88df000 {
			compatible = "qcom,sdm845-qspi", "qcom,qspi-v1";
			reg = <0x0 0x88df000 0x0 0x600>;
			#address-cells = <0x1>;
			#size-cells = <0x0>;
			interrupts = <0x0 0x52 0x4>;
			clocks = <0x10 0xbd 0x10 0xbc>;
			clock-names = "iface", "core";
			status = "disabled";
		};

		phy@88e2000 {
			compatible = "qcom,sdm845-qusb2-phy";
			reg = <0x0 0x88e2000 0x0 0x400>;
			status = "okay";
			#phy-cells = <0x0>;
			clocks = <0x10 0xa1 0x4b 0x0>;
			clock-names = "cfg_ahb", "ref";
			resets = <0x10 0x8>;
			nvmem-cells = <0x4f>;
			vdd-supply = <0x4d>;
			vdda-pll-supply = <0x50>;
			vdda-phy-dpdm-supply = <0x51>;
			qcom,imp-res-offset-value = <0x8>;
			qcom,hstx-trim-value = <0x4>;
			qcom,preemphasis-level = <0x1>;
			qcom,preemphasis-width = <0x1>;
			phandle = <0x53>;
		};

		phy@88e3000 {
			compatible = "qcom,sdm845-qusb2-phy";
			reg = <0x0 0x88e3000 0x0 0x400>;
			status = "okay";
			#phy-cells = <0x0>;
			clocks = <0x10 0xa1 0x4b 0x0>;
			clock-names = "cfg_ahb", "ref";
			resets = <0x10 0x9>;
			nvmem-cells = <0x52>;
			vdd-supply = <0x4d>;
			vdda-pll-supply = <0x50>;
			vdda-phy-dpdm-supply = <0x51>;
			qcom,imp-res-offset-value = <0x8>;
			qcom,hstx-trim-value = <0x2>;
			phandle = <0x55>;
		};

		phy@88e9000 {
			compatible = "qcom,sdm845-qmp-usb3-phy";
			reg = <0x0 0x88e9000 0x0 0x18c 0x0 0x88e8000 0x0 0x10>;
			reg-names = "reg-base", "dp_com";
			status = "okay";
			#clock-cells = <0x1>;
			#address-cells = <0x2>;
			#size-cells = <0x2>;
			ranges;
			clocks = <0x10 0x98 0x10 0xa1 0x10 0x97 0x10 0x9a>;
			clock-names = "aux", "cfg_ahb", "ref", "com_aux";
			resets = <0x10 0x13 0x10 0x11>;
			reset-names = "phy", "common";
			vdda-phy-supply = <0x4e>;
			vdda-pll-supply = <0x4d>;

			lanes@88e9200 {
				reg = <0x0 0x88e9200 0x0 0x128 0x0 0x88e9400 0x0 0x200 0x0 0x88e9c00 0x0 0x218 0x0 0x88e9600 0x0 0x128 0x0 0x88e9800 0x0 0x200 0x0 0x88e9a00 0x0 0x100>;
				#phy-cells = <0x0>;
				clocks = <0x10 0x9b>;
				clock-names = "pipe0";
				clock-output-names = "usb3_phy_pipe_clk_src";
				phandle = <0x54>;
			};
		};

		phy@88eb000 {
			compatible = "qcom,sdm845-qmp-usb3-uni-phy";
			reg = <0x0 0x88eb000 0x0 0x18c>;
			status = "okay";
			#clock-cells = <0x1>;
			#address-cells = <0x2>;
			#size-cells = <0x2>;
			ranges;
			clocks = <0x10 0x9d 0x10 0xa1 0x10 0x9c 0x10 0xa0>;
			clock-names = "aux", "cfg_ahb", "ref", "com_aux";
			resets = <0x10 0x15 0x10 0x14>;
			reset-names = "phy", "common";
			vdda-phy-supply = <0x4e>;
			vdda-pll-supply = <0x4d>;

			lane@88eb200 {
				reg = <0x0 0x88eb200 0x0 0x128 0x0 0x88eb400 0x0 0x1fc 0x0 0x88eb800 0x0 0x218 0x0 0x88eb600 0x0 0x70>;
				#phy-cells = <0x0>;
				clocks = <0x10 0x9f>;
				clock-names = "pipe0";
				clock-output-names = "usb3_uni_phy_pipe_clk_src";
				phandle = <0x56>;
			};
		};

		usb@a6f8800 {
			compatible = "qcom,sdm845-dwc3", "qcom,dwc3";
			reg = <0x0 0xa6f8800 0x0 0x400>;
			status = "okay";
			#address-cells = <0x2>;
			#size-cells = <0x2>;
			ranges;
			clocks = <0x10 0xc 0x10 0x8d 0x10 0x3 0x10 0x8f 0x10 0x91>;
			clock-names = "cfg_noc", "core", "iface", "mock_utmi", "sleep";
			assigned-clocks = <0x10 0x8f 0x10 0x8d>;
			assigned-clock-rates = <0x124f800 0x8f0d180>;
			interrupts = <0x0 0x83 0x4 0x0 0x1e6 0x4 0x0 0x1e8 0x4 0x0 0x1e9 0x4>;
			interrupt-names = "hs_phy_irq", "ss_phy_irq", "dm_hs_phy_irq", "dp_hs_phy_irq";
			power-domains = <0x10 0x4>;
			resets = <0x10 0xf>;

			dwc3@a600000 {
				compatible = "snps,dwc3";
				reg = <0x0 0xa600000 0x0 0xcd00>;
				interrupts = <0x0 0x85 0x4>;
				snps,dis_u2_susphy_quirk;
				snps,dis_enblslpm_quirk;
				phys = <0x53 0x54>;
				phy-names = "usb2-phy", "usb3-phy";
				dr_mode = "host";
			};
		};

		usb@a8f8800 {
			compatible = "qcom,sdm845-dwc3", "qcom,dwc3";
			reg = <0x0 0xa8f8800 0x0 0x400>;
			status = "okay";
			#address-cells = <0x2>;
			#size-cells = <0x2>;
			ranges;
			clocks = <0x10 0xd 0x10 0x92 0x10 0x4 0x10 0x94 0x10 0x96>;
			clock-names = "cfg_noc", "core", "iface", "mock_utmi", "sleep";
			assigned-clocks = <0x10 0x94 0x10 0x92>;
			assigned-clock-rates = <0x124f800 0x8f0d180>;
			interrupts = <0x0 0x88 0x4 0x0 0x1e7 0x4 0x0 0x1ea 0x4 0x0 0x1eb 0x4>;
			interrupt-names = "hs_phy_irq", "ss_phy_irq", "dm_hs_phy_irq", "dp_hs_phy_irq";
			power-domains = <0x10 0x5>;
			resets = <0x10 0x10>;

			dwc3@a800000 {
				compatible = "snps,dwc3";
				reg = <0x0 0xa800000 0x0 0xcd00>;
				interrupts = <0x0 0x8a 0x4>;
				snps,dis_u2_susphy_quirk;
				snps,dis_enblslpm_quirk;
				phys = <0x55 0x56>;
				phy-names = "usb2-phy", "usb3-phy";
				dr_mode = "host";
			};
		};

		clock-controller@ab00000 {
			compatible = "qcom,sdm845-videocc";
			reg = <0x0 0xab00000 0x0 0x10000>;
			#clock-cells = <0x1>;
			#power-domain-cells = <0x1>;
			#reset-cells = <0x1>;
		};

		mdss@ae00000 {
			compatible = "qcom,sdm845-mdss";
			reg = <0x0 0xae00000 0x0 0x1000>;
			reg-names = "mdss";
			power-domains = <0x57 0x0>;
			clocks = <0x10 0x13 0x10 0x14 0x57 0xc>;
			clock-names = "iface", "bus", "core";
			assigned-clocks = <0x57 0xc>;
			assigned-clock-rates = <0x11e1a300>;
			interrupts = <0x0 0x53 0x4>;
			interrupt-controller;
			#interrupt-cells = <0x1>;
			iommus = <0x4a 0x880 0x8 0x4a 0xc80 0x8>;
			status = "disabled";
			#address-cells = <0x2>;
			#size-cells = <0x2>;
			ranges;
			phandle = <0x58>;

			mdp@ae01000 {
				compatible = "qcom,sdm845-dpu";
				reg = <0x0 0xae01000 0x0 0x8f000 0x0 0xaeb0000 0x0 0x2008>;
				reg-names = "mdp", "vbif";
				clocks = <0x57 0x0 0x57 0x1 0x57 0xc 0x57 0x17>;
				clock-names = "iface", "bus", "core", "vsync";
				assigned-clocks = <0x57 0xc 0x57 0x17>;
				assigned-clock-rates = <0x11e1a300 0x124f800>;
				interrupt-parent = <0x58>;
				interrupts = <0x0 0x4>;
				status = "disabled";

				ports {
					#address-cells = <0x1>;
					#size-cells = <0x0>;

					port@0 {
						reg = <0x0>;

						endpoint {
							remote-endpoint = <0x59>;
							phandle = <0x5c>;
						};
					};

					port@1 {
						reg = <0x1>;

						endpoint {
							remote-endpoint = <0x5a>;
							phandle = <0x5e>;
						};
					};
				};
			};

			dsi@ae94000 {
				compatible = "qcom,mdss-dsi-ctrl";
				reg = <0x0 0xae94000 0x0 0x400>;
				reg-names = "dsi_ctrl";
				interrupt-parent = <0x58>;
				interrupts = <0x4 0x4>;
				clocks = <0x57 0x2 0x57 0x4 0x57 0xf 0x57 0x8 0x57 0x0 0x57 0x1>;
				clock-names = "byte", "byte_intf", "pixel", "core", "iface", "bus";
				phys = <0x5b>;
				phy-names = "dsi";
				status = "disabled";
				#address-cells = <0x1>;
				#size-cells = <0x0>;

				ports {
					#address-cells = <0x1>;
					#size-cells = <0x0>;

					port@0 {
						reg = <0x0>;

						endpoint {
							remote-endpoint = <0x5c>;
							phandle = <0x59>;
						};
					};

					port@1 {
						reg = <0x1>;

						endpoint {
						};
					};
				};
			};

			dsi-phy@ae94400 {
				compatible = "qcom,dsi-phy-10nm";
				reg = <0x0 0xae94400 0x0 0x200 0x0 0xae94600 0x0 0x280 0x0 0xae94a00 0x0 0x1e0>;
				reg-names = "dsi_phy", "dsi_phy_lane", "dsi_pll";
				#clock-cells = <0x1>;
				#phy-cells = <0x0>;
				clocks = <0x57 0x0>;
				clock-names = "iface";
				status = "disabled";
				phandle = <0x5b>;
			};

			dsi@ae96000 {
				compatible = "qcom,mdss-dsi-ctrl";
				reg = <0x0 0xae96000 0x0 0x400>;
				reg-names = "dsi_ctrl";
				interrupt-parent = <0x58>;
				interrupts = <0x5 0x4>;
				clocks = <0x57 0x5 0x57 0x7 0x57 0x11 0x57 0xa 0x57 0x0 0x57 0x1>;
				clock-names = "byte", "byte_intf", "pixel", "core", "iface", "bus";
				phys = <0x5d>;
				phy-names = "dsi";
				status = "disabled";
				#address-cells = <0x1>;
				#size-cells = <0x0>;

				ports {
					#address-cells = <0x1>;
					#size-cells = <0x0>;

					port@0 {
						reg = <0x0>;

						endpoint {
							remote-endpoint = <0x5e>;
							phandle = <0x5a>;
						};
					};

					port@1 {
						reg = <0x1>;

						endpoint {
						};
					};
				};
			};

			dsi-phy@ae96400 {
				compatible = "qcom,dsi-phy-10nm";
				reg = <0x0 0xae96400 0x0 0x200 0x0 0xae96600 0x0 0x280 0x0 0xae96a00 0x0 0x10e>;
				reg-names = "dsi_phy", "dsi_phy_lane", "dsi_pll";
				#clock-cells = <0x1>;
				#phy-cells = <0x0>;
				clocks = <0x57 0x0>;
				clock-names = "iface";
				status = "disabled";
				phandle = <0x5d>;
			};
		};

		clock-controller@af00000 {
			compatible = "qcom,sdm845-dispcc";
			reg = <0x0 0xaf00000 0x0 0x10000>;
			#clock-cells = <0x1>;
			#reset-cells = <0x1>;
			#power-domain-cells = <0x1>;
			phandle = <0x57>;
		};

		reset-controller@b2e0000 {
			compatible = "qcom,sdm845-pdc-global";
			reg = <0x0 0xb2e0000 0x0 0x20000>;
			#reset-cells = <0x1>;
		};

		thermal-sensor@c263000 {
			compatible = "qcom,sdm845-tsens", "qcom,tsens-v2";
			reg = <0x0 0xc263000 0x0 0x1ff 0x0 0xc222000 0x0 0x1ff>;
			#qcom,sensors = <0xd>;
			#thermal-sensor-cells = <0x1>;
			phandle = <0x63>;
		};

		thermal-sensor@c265000 {
			compatible = "qcom,sdm845-tsens", "qcom,tsens-v2";
			reg = <0x0 0xc265000 0x0 0x1ff 0x0 0xc223000 0x0 0x1ff>;
			#qcom,sensors = <0x8>;
			#thermal-sensor-cells = <0x1>;
		};

		reset-controller@c2a0000 {
			compatible = "qcom,sdm845-aoss-cc";
			reg = <0x0 0xc2a0000 0x0 0x31000>;
			#reset-cells = <0x1>;
		};

		spmi@c440000 {
			compatible = "qcom,spmi-pmic-arb";
			reg = <0x0 0xc440000 0x0 0x1100 0x0 0xc600000 0x0 0x2000000 0x0 0xe600000 0x0 0x100000 0x0 0xe700000 0x0 0xa0000 0x0 0xc40a000 0x0 0x26000>;
			reg-names = "core", "chnls", "obsrvr", "intr", "cnfg";
			interrupt-names = "periph_irq";
			interrupts = <0x0 0x1e1 0x4>;
			qcom,ee = <0x0>;
			qcom,channel = <0x0>;
			#address-cells = <0x2>;
			#size-cells = <0x0>;
			interrupt-controller;
			#interrupt-cells = <0x4>;
			cell-index = <0x0>;

			pmic@0 {
				compatible = "qcom,pm8998", "qcom,spmi-pmic";
				reg = <0x0 0x0>;
				#address-cells = <0x1>;
				#size-cells = <0x0>;

				pon@800 {
					compatible = "qcom,pm8916-pon";
					reg = <0x800>;
					mode-bootloader = <0x2>;
					mode-recovery = <0x1>;

					pwrkey {
						compatible = "qcom,pm8941-pwrkey";
						interrupts = <0x0 0x8 0x0 0x3>;
						debounce = <0x3d09>;
						bias-pull-up;
						linux,code = <0x74>;
					};
				};

				temp-alarm@2400 {
					compatible = "qcom,spmi-temp-alarm";
					reg = <0x2400>;
					interrupts = <0x0 0x24 0x0 0x1>;
					#thermal-sensor-cells = <0x0>;
					phandle = <0x64>;
				};

				coincell@2800 {
					compatible = "qcom,pm8941-coincell";
					reg = <0x2800>;
					status = "disabled";
				};

				adc@3100 {
					compatible = "qcom,spmi-adc-rev2";
					reg = <0x3100>;
					interrupts = <0x0 0x31 0x0 0x1>;
					#address-cells = <0x1>;
					#size-cells = <0x0>;
					#io-channel-cells = <0x1>;

					adc-chan@0x06 {
						reg = <0x6>;
						label = "die_temp";
					};
				};

				rtc@6000 {
					compatible = "qcom,pm8941-rtc";
					reg = <0x6000 0x6100>;
					reg-names = "rtc", "alarm";
					interrupts = <0x0 0x61 0x1 0x1>;
				};

				gpios@c000 {
					compatible = "qcom,pm8998-gpio", "qcom,spmi-gpio";
					reg = <0xc000>;
					gpio-controller;
					#gpio-cells = <0x2>;
					interrupt-controller;
					#interrupt-cells = <0x2>;
				};
			};

			pmic@1 {
				compatible = "qcom,pm8998", "qcom,spmi-pmic";
				reg = <0x1 0x0>;
				#address-cells = <0x1>;
				#size-cells = <0x0>;
			};
		};

		iommu@15000000 {
			compatible = "qcom,sdm845-smmu-500", "arm,mmu-500";
			reg = <0x0 0x15000000 0x0 0x80000>;
			#iommu-cells = <0x2>;
			#global-interrupts = <0x1>;
			interrupts = <0x0 0x41 0x4 0x0 0x60 0x4 0x0 0x61 0x4 0x0 0x62 0x4 0x0 0x63 0x4 0x0 0x64 0x4 0x0 0x65 0x4 0x0 0x66 0x4 0x0 0x67 0x4 0x0 0x68 0x4 0x0 0x69 0x4 0x0 0x6a 0x4 0x0 0x6b 0x4 0x0 0x6c 0x4 0x0 0x6d 0x4 0x0 0x6e 0x4 0x0 0x6f 0x4 0x0 0x70 0x4 0x0 0x71 0x4 0x0 0x72 0x4 0x0 0x73 0x4 0x0 0x74 0x4 0x0 0x75 0x4 0x0 0x76 0x4 0x0 0xb5 0x4 0x0 0xb6 0x4 0x0 0xb7 0x4 0x0 0xb8 0x4 0x0 0xb9 0x4 0x0 0xba 0x4 0x0 0xbb 0x4 0x0 0xbc 0x4 0x0 0xbd 0x4 0x0 0xbe 0x4 0x0 0xbf 0x4 0x0 0xc0 0x4 0x0 0x13b 0x4 0x0 0x13c 0x4 0x0 0x13d 0x4 0x0 0x13e 0x4 0x0 0x13f 0x4 0x0 0x140 0x4 0x0 0x141 0x4 0x0 0x142 0x4 0x0 0x143 0x4 0x0 0x144 0x4 0x0 0x145 0x4 0x0 0x146 0x4 0x0 0x147 0x4 0x0 0x148 0x4 0x0 0x149 0x4 0x0 0x14a 0x4 0x0 0x14b 0x4 0x0 0x14c 0x4 0x0 0x14d 0x4 0x0 0x14e 0x4 0x0 0x14f 0x4 0x0 0x150 0x4 0x0 0x151 0x4 0x0 0x152 0x4 0x0 0x153 0x4 0x0 0x154 0x4 0x0 0x155 0x4 0x0 0x156 0x4 0x0 0x157 0x4>;
			status = "disabled";
			phandle = <0x4a>;
		};

		clock-controller@17014000 {
			compatible = "qcom,sdm845-lpasscc";
			reg = <0x0 0x17014000 0x0 0x1f004 0x0 0x17300000 0x0 0x200>;
			reg-names = "cc", "qdsp6ss";
			#clock-cells = <0x1>;
			status = "disabled";
		};

		mailbox@17990000 {
			compatible = "qcom,sdm845-apss-shared";
			reg = <0x0 0x17990000 0x0 0x1000>;
			#mbox-cells = <0x1>;
			phandle = <0xf>;
		};

		rsc@179c0000 {
			label = "apps_rsc";
			compatible = "qcom,rpmh-rsc";
			reg = <0x0 0x179c0000 0x0 0x10000 0x0 0x179d0000 0x0 0x10000 0x0 0x179e0000 0x0 0x10000>;
			reg-names = "drv-0", "drv-1", "drv-2";
			interrupts = <0x0 0x3 0x4 0x0 0x4 0x4 0x0 0x5 0x4>;
			qcom,tcs-offset = <0xd00>;
			qcom,drv-id = <0x2>;
			qcom,tcs-config = <0x2 0x2 0x0 0x3 0x1 0x3 0x3 0x1>;

			clock-controller {
				compatible = "qcom,sdm845-rpmh-clk";
				#clock-cells = <0x1>;
				phandle = <0x4b>;
			};

			power-controller {
				compatible = "qcom,sdm845-rpmhpd";
				#power-domain-cells = <0x1>;
				operating-points-v2 = <0x5f>;

				opp-table {
					compatible = "operating-points-v2";
					phandle = <0x5f>;

					opp1 {
						opp-level = <0x10>;
					};

					opp2 {
						opp-level = <0x30>;
					};

					opp3 {
						opp-level = <0x40>;
					};

					opp4 {
						opp-level = <0x80>;
					};

					opp5 {
						opp-level = <0xc0>;
					};

					opp6 {
						opp-level = <0x100>;
					};

					opp7 {
						opp-level = <0x140>;
					};

					opp8 {
						opp-level = <0x150>;
					};

					opp9 {
						opp-level = <0x180>;
					};

					opp10 {
						opp-level = <0x1a0>;
					};
				};
			};

			interconnect {
				compatible = "qcom,sdm845-rsc-hlos";
				#interconnect-cells = <0x1>;
			};

			pm8998-rpmh-regulators {
				compatible = "qcom,pm8998-rpmh-regulators";
				qcom,pmic-id = [61 00];
				vdd-l2-l8-l17-supply = <0x60>;
				vdd-l7-l12-l14-l15-supply = <0x61>;

				smps2 {
				};

				smps3 {
					regulator-min-microvolt = <0x14a140>;
					regulator-max-microvolt = <0x14a140>;
					regulator-initial-mode = <0x3>;
					phandle = <0x60>;
				};

				smps4 {
					regulator-min-microvolt = <0x1b7740>;
					regulator-max-microvolt = <0x1b7740>;
					regulator-initial-mode = <0x3>;
					phandle = <0x29>;
				};

				smps5 {
					regulator-min-microvolt = <0x1f20c0>;
					regulator-max-microvolt = <0x1f20c0>;
					regulator-initial-mode = <0x3>;
					phandle = <0x61>;
				};

				smps7 {
				};

				ldo1 {
					regulator-min-microvolt = <0xd6d80>;
					regulator-max-microvolt = <0xd6d80>;
					regulator-initial-mode = <0x3>;
					phandle = <0x4d>;
				};

				ldo2 {
					regulator-min-microvolt = <0x124f80>;
					regulator-max-microvolt = <0x124f80>;
					regulator-initial-mode = <0x3>;
					regulator-always-on;
				};

				ldo3 {
				};

				ldo5 {
					regulator-min-microvolt = <0xc3500>;
					regulator-max-microvolt = <0xc3500>;
					regulator-initial-mode = <0x3>;
				};

				ldo6 {
					regulator-min-microvolt = <0x1b7740>;
					regulator-max-microvolt = <0x1b7740>;
					regulator-initial-mode = <0x3>;
				};

				ldo7 {
					regulator-min-microvolt = <0x1b7740>;
					regulator-max-microvolt = <0x1b7740>;
					regulator-initial-mode = <0x3>;
					phandle = <0x2a>;
				};

				ldo8 {
				};

				ldo9 {
				};

				ldo10 {
				};

				ldo11 {
				};

				ldo12 {
					regulator-min-microvolt = <0x1b7740>;
					regulator-max-microvolt = <0x1b7740>;
					regulator-initial-mode = <0x3>;
					phandle = <0x50>;
				};

				ldo13 {
				};

				ldo14 {
					regulator-min-microvolt = <0x1cafc0>;
					regulator-max-microvolt = <0x1cafc0>;
					regulator-initial-mode = <0x3>;
				};

				ldo15 {
				};

				ldo16 {
				};

				ldo17 {
					regulator-min-microvolt = <0x13e5c0>;
					regulator-max-microvolt = <0x13e5c0>;
					regulator-initial-mode = <0x3>;
					phandle = <0x2b>;
				};

				ldo18 {
				};

				ldo19 {
					regulator-min-microvolt = <0x2f4d60>;
					regulator-max-microvolt = <0x2f6ca0>;
					regulator-initial-mode = <0x3>;
				};

				ldo20 {
					regulator-min-microvolt = <0x2d2a80>;
					regulator-max-microvolt = <0x2d2a80>;
					regulator-initial-mode = <0x3>;
					phandle = <0x4c>;
				};

				ldo21 {
				};

				ldo22 {
				};

				ldo23 {
				};

				ldo24 {
					regulator-min-microvolt = <0x2eebb8>;
					regulator-max-microvolt = <0x2f0af8>;
					regulator-initial-mode = <0x3>;
					phandle = <0x51>;
				};

				ldo25 {
					regulator-min-microvolt = <0x2f5d00>;
					regulator-max-microvolt = <0x2f7c40>;
					regulator-initial-mode = <0x3>;
					phandle = <0x2c>;
				};

				ldo26 {
					regulator-min-microvolt = <0x124f80>;
					regulator-max-microvolt = <0x126ec0>;
					regulator-initial-mode = <0x3>;
					phandle = <0x4e>;
				};

				ldo28 {
				};

				lvs1 {
				};

				lvs2 {
				};
			};
		};

		interrupt-controller@17a00000 {
			compatible = "arm,gic-v3";
			#address-cells = <0x2>;
			#size-cells = <0x2>;
			ranges;
			#interrupt-cells = <0x3>;
			interrupt-controller;
			reg = <0x0 0x17a00000 0x0 0x10000 0x0 0x17a60000 0x0 0x100000>;
			interrupts = <0x1 0x9 0x4>;
			phandle = <0x1>;

			gic-its@17a40000 {
				compatible = "arm,gic-v3-its";
				msi-controller;
				#msi-cells = <0x1>;
				reg = <0x0 0x17a40000 0x0 0x20000>;
				status = "disabled";
			};
		};

		timer@17c90000 {
			#address-cells = <0x2>;
			#size-cells = <0x2>;
			ranges;
			compatible = "arm,armv7-timer-mem";
			reg = <0x0 0x17c90000 0x0 0x1000>;

			frame@17ca0000 {
				frame-number = <0x0>;
				interrupts = <0x0 0x7 0x4 0x0 0x6 0x4>;
				reg = <0x0 0x17ca0000 0x0 0x1000 0x0 0x17cb0000 0x0 0x1000>;
			};

			frame@17cc0000 {
				frame-number = <0x1>;
				interrupts = <0x0 0x8 0x4>;
				reg = <0x0 0x17cc0000 0x0 0x1000>;
				status = "disabled";
			};

			frame@17cd0000 {
				frame-number = <0x2>;
				interrupts = <0x0 0x9 0x4>;
				reg = <0x0 0x17cd0000 0x0 0x1000>;
				status = "disabled";
			};

			frame@17ce0000 {
				frame-number = <0x3>;
				interrupts = <0x0 0xa 0x4>;
				reg = <0x0 0x17ce0000 0x0 0x1000>;
				status = "disabled";
			};

			frame@17cf0000 {
				frame-number = <0x4>;
				interrupts = <0x0 0xb 0x4>;
				reg = <0x0 0x17cf0000 0x0 0x1000>;
				status = "disabled";
			};

			frame@17d00000 {
				frame-number = <0x5>;
				interrupts = <0x0 0xc 0x4>;
				reg = <0x0 0x17d00000 0x0 0x1000>;
				status = "disabled";
			};

			frame@17d10000 {
				frame-number = <0x6>;
				interrupts = <0x0 0xd 0x4>;
				reg = <0x0 0x17d10000 0x0 0x1000>;
				status = "disabled";
			};
		};

		cpufreq@17d43000 {
			compatible = "qcom,cpufreq-hw";
			reg = <0x0 0x17d43000 0x0 0x1400 0x0 0x17d45800 0x0 0x1400>;
			reg-names = "freq-domain0", "freq-domain1";
			clocks = <0x4b 0x0 0x10 0xa5>;
			clock-names = "xo", "alternate";
			#freq-domain-cells = <0x1>;
			phandle = <0x2>;
		};

		wifi@18800000 {
			compatible = "qcom,wcn3990-wifi";
			status = "disabled";
			reg = <0x0 0x18800000 0x0 0x800000>;
			reg-names = "membase";
			memory-region = <0x62>;
			interrupts = <0x0 0x19e 0x4 0x0 0x19f 0x4 0x0 0x1a0 0x4 0x0 0x1a1 0x4 0x0 0x1a2 0x4 0x0 0x1a3 0x4 0x0 0x1a4 0x4 0x0 0x1a5 0x4 0x0 0x1a6 0x4 0x0 0x1a7 0x4 0x0 0x1a8 0x4 0x0 0x1a9 0x4>;
		};
	};

	thermal-zones {

		cpu0-thermal {
			polling-delay-passive = <0xfa>;
			polling-delay = <0x3e8>;
			thermal-sensors = <0x63 0x1>;

			trips {

				trip0 {
					temperature = <0x124f8>;
					hysteresis = <0x7d0>;
					type = "passive";
				};

				trip1 {
					temperature = <0x1adb0>;
					hysteresis = <0x3e8>;
					type = "critical";
				};
			};
		};

		cpu1-thermal {
			polling-delay-passive = <0xfa>;
			polling-delay = <0x3e8>;
			thermal-sensors = <0x63 0x2>;

			trips {

				trip0 {
					temperature = <0x124f8>;
					hysteresis = <0x7d0>;
					type = "passive";
				};

				trip1 {
					temperature = <0x1adb0>;
					hysteresis = <0x3e8>;
					type = "critical";
				};
			};
		};

		cpu2-thermal {
			polling-delay-passive = <0xfa>;
			polling-delay = <0x3e8>;
			thermal-sensors = <0x63 0x3>;

			trips {

				trip0 {
					temperature = <0x124f8>;
					hysteresis = <0x7d0>;
					type = "passive";
				};

				trip1 {
					temperature = <0x1adb0>;
					hysteresis = <0x3e8>;
					type = "critical";
				};
			};
		};

		cpu3-thermal {
			polling-delay-passive = <0xfa>;
			polling-delay = <0x3e8>;
			thermal-sensors = <0x63 0x4>;

			trips {

				trip0 {
					temperature = <0x124f8>;
					hysteresis = <0x7d0>;
					type = "passive";
				};

				trip1 {
					temperature = <0x1adb0>;
					hysteresis = <0x3e8>;
					type = "critical";
				};
			};
		};

		cpu4-thermal {
			polling-delay-passive = <0xfa>;
			polling-delay = <0x3e8>;
			thermal-sensors = <0x63 0x7>;

			trips {

				trip0 {
					temperature = <0x124f8>;
					hysteresis = <0x7d0>;
					type = "passive";
				};

				trip1 {
					temperature = <0x1adb0>;
					hysteresis = <0x3e8>;
					type = "critical";
				};
			};
		};

		cpu5-thermal {
			polling-delay-passive = <0xfa>;
			polling-delay = <0x3e8>;
			thermal-sensors = <0x63 0x8>;

			trips {

				trip0 {
					temperature = <0x124f8>;
					hysteresis = <0x7d0>;
					type = "passive";
				};

				trip1 {
					temperature = <0x1adb0>;
					hysteresis = <0x3e8>;
					type = "critical";
				};
			};
		};

		cpu6-thermal {
			polling-delay-passive = <0xfa>;
			polling-delay = <0x3e8>;
			thermal-sensors = <0x63 0x9>;

			trips {

				trip0 {
					temperature = <0x124f8>;
					hysteresis = <0x7d0>;
					type = "passive";
				};

				trip1 {
					temperature = <0x1adb0>;
					hysteresis = <0x3e8>;
					type = "critical";
				};
			};
		};

		cpu7-thermal {
			polling-delay-passive = <0xfa>;
			polling-delay = <0x3e8>;
			thermal-sensors = <0x63 0xa>;

			trips {

				trip0 {
					temperature = <0x124f8>;
					hysteresis = <0x7d0>;
					type = "passive";
				};

				trip1 {
					temperature = <0x1adb0>;
					hysteresis = <0x3e8>;
					type = "critical";
				};
			};
		};

		pm8998 {
			polling-delay-passive = <0xfa>;
			polling-delay = <0x3e8>;
			thermal-sensors = <0x64>;

			trips {

				pm8998-alert0 {
					temperature = <0x19a28>;
					hysteresis = <0x7d0>;
					type = "passive";
				};

				pm8998-crit {
					temperature = <0x1e848>;
					hysteresis = <0x7d0>;
					type = "critical";
				};
			};
		};
	};
};
